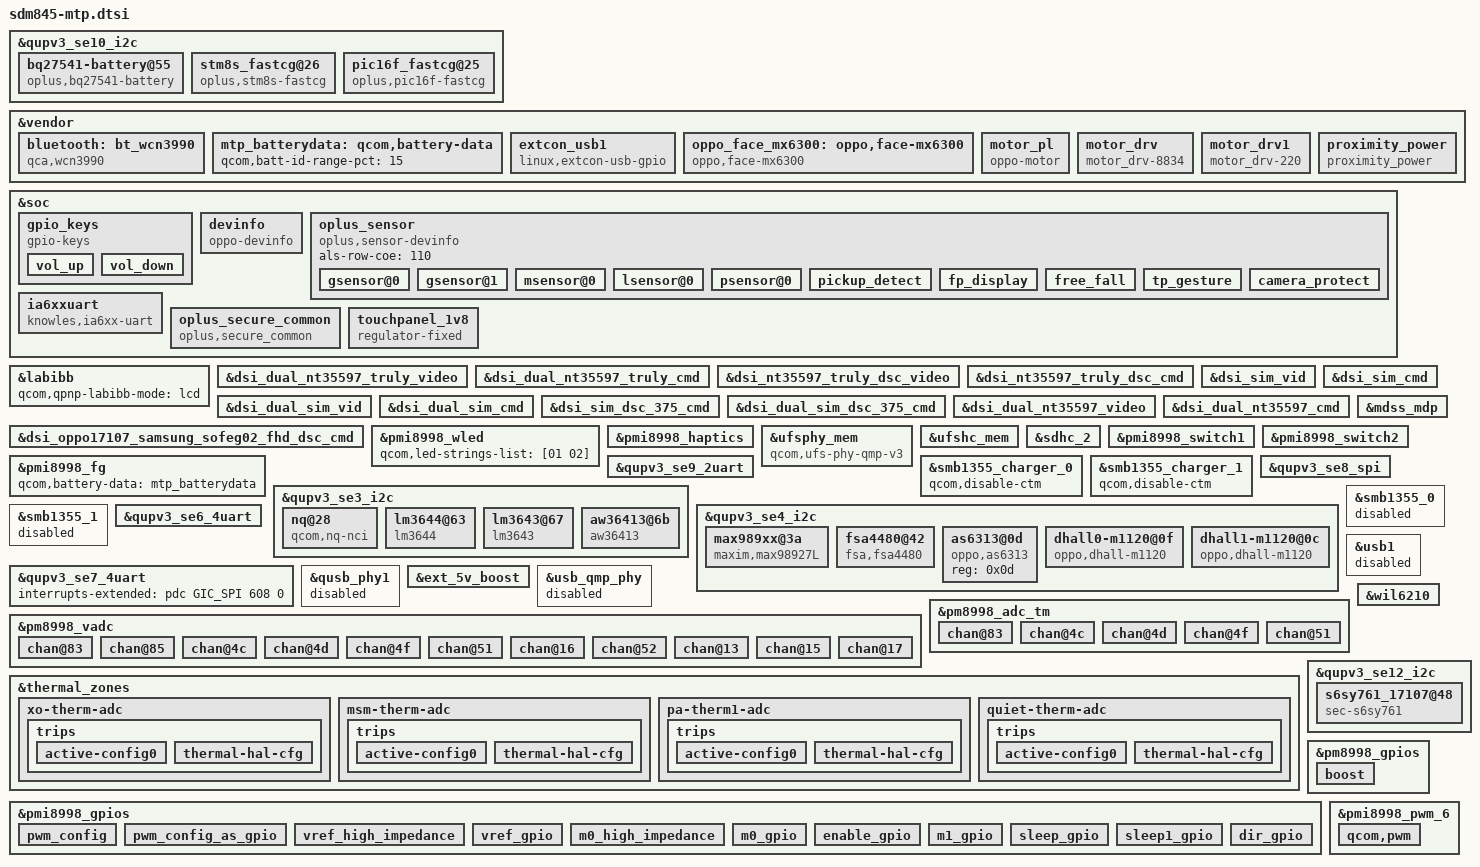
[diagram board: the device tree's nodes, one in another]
/* Copyright (c) 2016-2019, The Linux Foundation. All rights reserved.
 *
 * This program is free software; you can redistribute it and/or modify
 * it under the terms of the GNU General Public License version 2 and
 * only version 2 as published by the Free Software Foundation.
 *
 * This program is distributed in the hope that it will be useful,
 * but WITHOUT ANY WARRANTY; without even the implied warranty of
 * MERCHANTABILITY or FITNESS FOR A PARTICULAR PURPOSE.  See the
 * GNU General Public License for more details.
 */

#include <dt-bindings/gpio/gpio.h>
#include "sdm845-pmic-overlay.dtsi"
#include "sdm845-pinctrl-overlay.dtsi"
#include "sdm845-camera-sensor-mtp.dtsi"

&qupv3_se10_i2c {
#include "smb1355.dtsi"
};

&vendor {
	bluetooth: bt_wcn3990 {
		compatible = "qca,wcn3990";
		qca,bt-vdd-io-supply = <&pm8998_s3>;
		qca,bt-vdd-xtal-supply = <&pm8998_s5>;
		qca,bt-vdd-core-supply = <&pm8998_l7>;
		qca,bt-vdd-pa-supply = <&pm8998_l17>;
		qca,bt-vdd-ldo-supply = <&pm8998_l25>;

		qca,bt-vdd-io-voltage-level = <1352000 1352000>;
		qca,bt-vdd-xtal-voltage-level = <2040000 2040000>;
		qca,bt-vdd-core-voltage-level = <1800000 1800000>;
		qca,bt-vdd-pa-voltage-level = <1304000 1304000>;
		qca,bt-vdd-ldo-voltage-level = <3312000 3312000>;

		qca,bt-vdd-io-current-level = <1>; /* LPM/PFM */
		qca,bt-vdd-xtal-current-level = <1>; /* LPM/PFM */
		qca,bt-vdd-core-current-level = <1>; /* LPM/PFM */
		qca,bt-vdd-pa-current-level = <1>; /* LPM/PFM */
		qca,bt-vdd-ldo-current-level = <1>; /* LPM/PFM */
	};
};

&soc {
	gpio_keys {
		compatible = "gpio-keys";
		label = "gpio-keys";

		pinctrl-names = "default";
		pinctrl-0 = <&key_vol_up_default
			/*ifdef VENDOR_EDIT*/
			    &key_vol_down_default>;
			//#else
			//&key_cam_snapshot_default
			//&key_cam_focus_default>;
			/*endif*/

		vol_up {
			label = "volume_up";
			gpios = <&pm8998_gpios 6 GPIO_ACTIVE_LOW>;
			linux,input-type = <1>;
			linux,code = <115>;
			gpio-key,wakeup;
			debounce-interval = <15>;
			linux,can-disable;
		};
		/*ifdef VENDOR_EDIT*/
		vol_down {
			label = "volume_down";
			gpios = <&pm8998_gpios 5 GPIO_ACTIVE_LOW>;
			linux,input-type = <1>;
			linux,code = <114>;
			gpio-key,wakeup;
			debounce-interval = <15>;
			linux,can-disable;
		};
		/*endif*/

		/*
		cam_snapshot {
			label = "cam_snapshot";
			gpios = <&pm8998_gpios 7 GPIO_ACTIVE_LOW>;
			linux,input-type = <1>;
			linux,code = <766>;
			gpio-key,wakeup;
			debounce-interval = <15>;
			linux,can-disable;
		};

		cam_focus {
			label = "cam_focus";
			gpios = <&pm8998_gpios 8 GPIO_ACTIVE_LOW>;
			linux,input-type = <1>;
			linux,code = <528>;
			gpio-key,wakeup;
			debounce-interval = <15>;
			linux,can-disable;
		};
		*/
	};
	/*ifdef VENDOR_EDIT*/
	devinfo {
		compatible = "oppo-devinfo";
		Hw,sub_hwid_1 = <&tlmm 24 0x00>;
		Hw,high_version = <&tlmm 116 0x00>;
		pinctrl-names = "default","hw_sub_gpio_sleep", "high_version_active", "high_version_sleep";
		pinctrl-0 = <&hw_sub_gpio_active>;
		pinctrl-1 = <&hw_sub_gpio_sleep>;
		pinctrl-2 = <&hw_version_active>;
		pinctrl-3 = <&hw_version_sleep>;
	};
	/*endif*/


  //#ifdef VENDOR_EDIT
  /*yajie.chen @BSP.sensor, 2020/04/03, Add for sensor dts*/
  /*enum sensor_id { OPPO_ACCEL,OPPO_GYRO,OPPO_MAG,OPPO_LIGHT,OPPO_PROXIMITY,OPPO_SAR,OPPO_CT,OPPO_BAROMETER,SENSORS_NUM};*/
  oplus_sensor {
	compatible = "oplus,sensor-devinfo";
	als-row-coe = <110>;
	/*enum {LSM6DSM = 0x01, BMI160 = 0x02, LSM6DS3 = 0x04};*/
	gsensor@0 {
		sensor-name = <0x02>;//BMI160
		sensor-direction = <4>;
		sensor-index = <0>;//source num
		sensor-type = <0>;//OPPO_ACCEL
	};
	gsensor@1 {
		sensor-name = <0x01>;//LSM6DSM
		sensor-direction = <6>;
		sensor-index = <1>;//source num
		sensor-type = <0>;//OPPO_ACCEL
	};
	/* enum {AKM0991X = 0x01, MMC5603 = 0x02};*/
	msensor@0 {
		sensor-name = <0x01>;//AKM09918
		sensor-direction = <0>;
		sensor-index = <0>;
		sensor-type = <2>;//OPPO_MAG
		parameter-number= <18>;
		//soft-mag-parameter = <10489 0 194 0 95 1 194 0 9221 0 68 1 95 1 68 1 10344 0>;//e00 sign e01 sign...
	};
	/*enum {STK3A5X=0x01,TCS3701=0x02,TCS3408=0x04};*/
	lsensor@0 {
		sensor-name = <0x02>;//TCS3701
		sensor-index = <0>;
		sensor-type = <3>;//OPPO_MAG
		bus-number = <5>;
		irq-number = <89>;
		als-type = <2>;
		is-unit-device = <1>;
		is-als-dri = <1>;
		als-factor = <110>;
		is_als_initialed = <0>;
		als_buffer_length = <10>;
	};
	psensor@0 {
		sensor-name = <0x02>;//TCS3701
		sensor-index = <0>;
		sensor-type = <4>;//OPPO_PROXIMITY
		bus-number = <5>;
		irq-number = <89>;
		ps-cail-type = <2>;
		ps-type = <1>;
		is_ps_initialzed = <0>;
		low_step = <300>;
		high_step = <400>;
		low_limit = <400>;
		high_limit = <600>;
		dirty_low_step = <100>;
		dirty_high_step = <150>;
		ps_dirty_limit = <1020>;
		ps_ir_limit = <500>;
		ps_adjust_min = <0>;
		ps_adjust_max = <600>;
		sampling_count = <5>;
		step_max = <400>;
		step_min = <100>;
		step_div = <1500>;
		anti_shake_delta = <80>;
		dynamic_cali_max = <1024>;
		raw2offset_radio = <20800>;
		offset_max = <250>;
		offset_range_min = <0xFFFFFF01>;// -255
		offset_range_max = <255>;
		force_cali_limit = <2000>;
		cali_jitter_limit = <20>;
			cal_offset_margin = <80>;
		};
		/*virtual sensor
		enum sensor_algo_id {
			OPPO_PICKUP_DETECT,
			OPPO_LUX_AOD,
			OPPO_TP_GESTURE,
			OPPO_FP_DISPLAY,
			OPPO_FREE_FALL,
			OPPO_CAMERA_PROTECT,
			SENSOR_ALGO_NUM
		}*/
		pickup_detect {
			sensor-type = <0>; //OPPO_PICKUP_DETECT
			is-virtual-sensor;
			is-need-prox = <0>;
			prox-type = <0>; // 0 - proximity; 1 - proximity_fake
		};
		/*
		lux_aod {
			sensor-type = <1>; //OPPO_LUX_AOD
			is-virtual-sensor;
			thrd-low = <12>;
			thrd-high = <50>;
			als-type = <1>; // 0 - wise_light; 1 - ambient_light
		};
		*/
		fp_display {
			sensor-type = <3>; //OPPO_FP_DISPLAY
			is-virtual-sensor;
			prox-type = <0>; // 0 - proximity; 1 - proximity_fake
		};
		free_fall {
			sensor-type = <4>; //OPPO_FREE_FALL
			is-virtual-sensor;
		};
		tp_gesture {
			sensor-type = <2>; //OPPO_TP_GESTURE
			is-virtual-sensor;
		};
		camera_protect {
			sensor-type = <5>; //OPPO_CAMERA_PROTECT
			is-virtual-sensor;
			layout_offset_x = <65362>;
			layout_offset_y = <474>;
			init_pin = <17>;
			is_chip_pin = <0>;
		};
	};
	//#endif /*VENDOR_EDIT*/

/*#ifdef OPLUS_ARCH_EXTENDS */
	ia6xxuart {
		status = "ok";
		compatible = "knowles,ia6xx-uart";
		adnc,irq-pin = <&tlmm 80 0>;
		adnc,ldo-en-pin = <&tlmm 1 0>;
		adnc,reset = <&tlmm 25 0x00>;
		pinctrl-names = "default","adnc_reset_sleep";
		pinctrl-0 = <&adnc_reset_active>;
		pinctrl-1 = <&adnc_reset_sleep>;
	};
/*#endif OPLUS_ARCH_EXTENDS */

/* #ifdef OPLUS_FEATURE_SECURITY_COMMON */
	oplus_secure_common { //Slave driver and CS ID
                compatible = "oplus,secure_common"; //Manufacture, and Model
        };
/*#endif OPLUS_FEATURE_SECURITY_COMMON */
};


&labibb {
	status = "ok";
	qcom,qpnp-labibb-mode = "lcd";
};

&dsi_dual_nt35597_truly_video {
	qcom,panel-supply-entries = <&dsi_panel_pwr_supply>;
	qcom,mdss-dsi-bl-pmic-control-type = "bl_ctrl_wled";
	qcom,mdss-dsi-bl-min-level = <1>;
	qcom,mdss-dsi-bl-max-level = <4095>;
	qcom,mdss-dsi-mode-sel-gpio-state = "dual_port";
	qcom,panel-mode-gpio = <&tlmm 52 0>;
	qcom,platform-reset-gpio = <&tlmm 6 0>;
};

&dsi_dual_nt35597_truly_cmd {
	qcom,panel-supply-entries = <&dsi_panel_pwr_supply>;
	qcom,mdss-dsi-bl-pmic-control-type = "bl_ctrl_wled";
	qcom,mdss-dsi-bl-min-level = <1>;
	qcom,mdss-dsi-bl-max-level = <4095>;
	qcom,mdss-dsi-mode-sel-gpio-state = "dual_port";
	qcom,panel-mode-gpio = <&tlmm 52 0>;
	qcom,platform-reset-gpio = <&tlmm 6 0>;
	qcom,platform-te-gpio = <&tlmm 10 0>;
};

&dsi_nt35597_truly_dsc_video {
	qcom,panel-supply-entries = <&dsi_panel_pwr_supply>;
	qcom,mdss-dsi-bl-pmic-control-type = "bl_ctrl_wled";
	qcom,mdss-dsi-bl-min-level = <1>;
	qcom,mdss-dsi-bl-max-level = <4095>;
	qcom,mdss-dsi-mode-sel-gpio-state = "single_port";
	qcom,panel-mode-gpio = <&tlmm 52 0>;
	qcom,platform-reset-gpio = <&tlmm 6 0>;
};

&dsi_nt35597_truly_dsc_cmd {
	qcom,panel-supply-entries = <&dsi_panel_pwr_supply>;
	qcom,mdss-dsi-bl-pmic-control-type = "bl_ctrl_wled";
	qcom,mdss-dsi-bl-min-level = <1>;
	qcom,mdss-dsi-bl-max-level = <4095>;
	qcom,mdss-dsi-mode-sel-gpio-state = "single_port";
	qcom,panel-mode-gpio = <&tlmm 52 0>;
	qcom,platform-reset-gpio = <&tlmm 6 0>;
	qcom,platform-te-gpio = <&tlmm 10 0>;
};

&dsi_sim_vid {
	qcom,panel-supply-entries = <&dsi_panel_pwr_supply>;
	qcom,mdss-dsi-bl-pmic-control-type = "bl_ctrl_wled";
	qcom,platform-reset-gpio = <&tlmm 6 0>;
};

&dsi_dual_sim_vid {
	qcom,panel-supply-entries = <&dsi_panel_pwr_supply>;
	qcom,mdss-dsi-bl-pmic-control-type = "bl_ctrl_wled";
	qcom,platform-reset-gpio = <&tlmm 6 0>;
};

&dsi_sim_cmd {
	qcom,panel-supply-entries = <&dsi_panel_pwr_supply>;
	qcom,mdss-dsi-bl-pmic-control-type = "bl_ctrl_wled";
	qcom,platform-reset-gpio = <&tlmm 6 0>;
};

&dsi_dual_sim_cmd {
	qcom,panel-supply-entries = <&dsi_panel_pwr_supply>;
	qcom,mdss-dsi-bl-pmic-control-type = "bl_ctrl_wled";
	qcom,platform-reset-gpio = <&tlmm 6 0>;
};

&dsi_sim_dsc_375_cmd {
	qcom,panel-supply-entries = <&dsi_panel_pwr_supply>;
	qcom,mdss-dsi-bl-pmic-control-type = "bl_ctrl_wled";
	qcom,platform-reset-gpio = <&tlmm 6 0>;
};

&dsi_dual_sim_dsc_375_cmd {
	qcom,panel-supply-entries = <&dsi_panel_pwr_supply>;
	qcom,mdss-dsi-bl-pmic-control-type = "bl_ctrl_wled";
	qcom,platform-reset-gpio = <&tlmm 6 0>;
};

&dsi_dual_nt35597_video {
	qcom,panel-supply-entries = <&dsi_panel_pwr_supply>;
	qcom,mdss-dsi-bl-pmic-control-type = "bl_ctrl_wled";
	qcom,mdss-dsi-bl-min-level = <1>;
	qcom,mdss-dsi-bl-max-level = <4095>;
	qcom,mdss-dsi-mode-sel-gpio-state = "dual_port";
	qcom,panel-mode-gpio = <&tlmm 52 0>;
	qcom,platform-reset-gpio = <&tlmm 6 0>;
};

&dsi_dual_nt35597_cmd {
	qcom,panel-supply-entries = <&dsi_panel_pwr_supply>;
	qcom,mdss-dsi-bl-pmic-control-type = "bl_ctrl_wled";
	qcom,mdss-dsi-bl-min-level = <1>;
	qcom,mdss-dsi-bl-max-level = <4095>;
	qcom,mdss-dsi-mode-sel-gpio-state = "dual_port";
	qcom,panel-mode-gpio = <&tlmm 52 0>;
	qcom,platform-reset-gpio = <&tlmm 6 0>;
	qcom,platform-te-gpio = <&tlmm 10 0>;
};

//&dsi_nt35597_truly_dsc_cmd_display {
//	qcom,dsi-display-active;
//};

&dsi_oppo17107_samsung_sofeg02_fhd_dsc_cmd{
	qcom,dsi-display-active;
};

//#ifdef VENDOR_EDIT
&dsi_oppo17107_samsung_sofeg02_fhd_dsc_cmd{
	qcom,panel-supply-entries = <&dsi_panel_pwr_supply_no_labibb>;
        qcom,panel-supply-oppo-hardware-march = <&dsi_panel_pwr_supply_vdd_no_labibb>;

	qcom,mdss-dsi-bl-min-level = <1>;
	qcom,mdss-dsi-mode-sel-gpio-state = "single_port";
	qcom,panel-mode-gpio = <&tlmm 52 0>;
	qcom,platform-te-gpio = <&tlmm 10 0>;
	qcom,platform-reset-gpio = <&tlmm 6 0>;
	qcom,platform-vci-control-gpio = <&tlmm 26 0>;
	//qcom,platform-poc-control-gpio = <&tlmm 25 0>;
};

&pmi8998_wled {
	status = "okay";
	qcom,led-strings-list = [01 02];
};

&pmi8998_haptics {
	status = "okay";
};

&mdss_mdp {
	#cooling-cells = <2>;
};

&ufsphy_mem {
	compatible = "qcom,ufs-phy-qmp-v3";

	vdda-phy-supply = <&pm8998_l1>; /* 0.88v */
	vdda-pll-supply = <&pm8998_l26>; /* 1.2v */
	vdda-phy-max-microamp = <62900>;
	vdda-pll-max-microamp = <18300>;

	status = "ok";
};

&ufshc_mem {
	vdd-hba-supply = <&ufs_phy_gdsc>;
	vdd-hba-fixed-regulator;
	vcc-supply = <&pm8998_l20>;
	vcc-voltage-level = <2950000 2960000>;
	vccq2-supply = <&pm8998_s4>;
	vcc-max-microamp = <600000>;
	vccq2-max-microamp = <600000>;

	qcom,vddp-ref-clk-supply = <&pm8998_l2>;
	qcom,vddp-ref-clk-max-microamp = <100>;

	status = "ok";
};

&sdhc_2 {
	vdd-supply = <&pm8998_l21>;
	qcom,vdd-voltage-level = <2950000 2960000>;
	qcom,vdd-current-level = <200 800000>;

	vdd-io-supply = <&pm8998_l13>;
	qcom,vdd-io-voltage-level = <1808000 2960000>;
	qcom,vdd-io-current-level = <200 22000>;

	pinctrl-names = "active", "sleep", "ds_400KHz",
			"ds_50MHz", "ds_100MHz", "ds_200MHz";
	pinctrl-0 = <&sdc2_clk_on  &sdc2_cmd_on &sdc2_data_on &storage_cd>;
	pinctrl-1 = <&sdc2_clk_off &sdc2_cmd_off &sdc2_data_off &storage_cd>;
	pinctrl-2 = <&sdc2_clk_ds_400KHz
			&sdc2_cmd_ds_400KHz &sdc2_data_ds_400KHz>;
	pinctrl-3 = <&sdc2_clk_ds_50MHz
			&sdc2_cmd_ds_50MHz &sdc2_data_ds_50MHz>;
	pinctrl-4 = <&sdc2_clk_ds_100MHz
			&sdc2_cmd_ds_100MHz &sdc2_data_ds_100MHz>;
	pinctrl-5 = <&sdc2_clk_ds_200MHz
			&sdc2_cmd_ds_200MHz &sdc2_data_ds_200MHz>;

	cd-gpios = <&tlmm 126 GPIO_ACTIVE_LOW>;

	status = "ok";
};

&pmi8998_switch1 {
	pinctrl-names = "led_enable", "led_disable";
	pinctrl-0 = <&flash_led3_front_en>;
	pinctrl-1 = <&flash_led3_front_dis>;
};

&pmi8998_switch2 {
	pinctrl-names = "led_enable", "led_disable";
	pinctrl-0 = <&flash_led3_iris_en>;
	pinctrl-1 = <&flash_led3_iris_dis>;
};

&vendor {
	mtp_batterydata: qcom,battery-data {
		qcom,batt-id-range-pct = <15>;
		#include "fg-gen3-batterydata-itech-3000mah.dtsi"
		#include "fg-gen3-batterydata-ascent-3450mah.dtsi"
		#include "fg-gen3-batterydata-demo-6000mah.dtsi"
	};

	extcon_usb1: extcon_usb1 {
		compatible = "linux,extcon-usb-gpio";
		vbus-gpio = <&pmi8998_gpios 8 GPIO_ACTIVE_HIGH>;

		pinctrl-names = "default";
		pinctrl-0 = <&usb2_vbus_det_default>;
	};
};

&pmi8998_fg {
	qcom,battery-data = <&mtp_batterydata>;
};

&smb1355_charger_0 {
	status = "ok";
	qcom,disable-ctm;
};

&smb1355_charger_1 {
	status = "ok";
	qcom,disable-ctm;
};

&qupv3_se9_2uart {
	status = "ok";
};

&qupv3_se8_spi {
	status = "ok";
};

&qupv3_se3_i2c {
	status = "ok";
	nq@28 {
		compatible = "qcom,nq-nci";
		reg = <0x28>;
		qcom,nq-irq = <&tlmm 63 0x00>;
		qcom,nq-ven = <&tlmm 12 0x00>;
		qcom,nq-firm = <&tlmm 62 0x00>;
		qcom,nq-clkreq = <&pm8998_gpios 21 0x00>;
		qcom,nq-esepwr = <&tlmm 116 0x00>;
		interrupt-parent = <&tlmm>;
		interrupts = <63 0>;
		interrupt-names = "nfc_irq";
		pinctrl-names = "nfc_active", "nfc_suspend";
		pinctrl-0 = <&nfc_int_active
			     &nfc_enable_active
			     &nfc_clk_default>;
		pinctrl-1 = <&nfc_int_suspend &nfc_enable_suspend>;
	};
};

/* #ifdef OPLUS_ARCH_EXTENDS */
&qupv3_se4_i2c {
	status = "ok";
	max989xx@3a {
		compatible = "maxim,max98927L";
		reg = <0x3a>;
		mono_stereo_mode = <0>;
		interleave_mode = <0>;
		maxim,98927-reset-gpio = <&tlmm 69 0x00>;
		max989xx_vdd-supply = <&pm8998_s4>;
		status = "okay";
	};
};
/* #endif OPLUS_ARCH_EXTENDS */




//#ifdef VENDOR_EDIT
&smb1355_0 {
	status = "disabled";
};
&smb1355_1 {
	status = "disabled";
};
//#endif //VENDOR_EDIT

/* #ifdef OPLUS_FEATURE_FACERECOGNITION  */
&qupv3_se3_i2c {
        status = "ok";
        lm3644@63 {
                compatible = "lm3644";
                reg = <0x63>;
                lm3644,hwen-gpio = <&tlmm 39 0x00>;
                lm3644,ldo-en-gpio = <&tlmm 40 0x00>;
                lm3644,watchdog-gpio = <&tlmm 81 0x00>;
                lm3644,watchdog-en-gpio = <&tlmm 33 0x00>;
                status = "okay";
        };
        lm3643@67 {
                compatible = "lm3643";
                reg = <0x67>;
                lm3643,hwen-gpio = <&tlmm 113 0x00>;
                status = "okay";
        };
        aw36413@6b {
                compatible = "aw36413";
                reg = <0x6b>;
                aw36413,hwen-gpio = <&tlmm 113 0x00>;
                status = "okay";
        };
};
/* #endif OPLUS_FEATURE_FACERECOGNITION  */

/* #ifdef OPLUS_ARCH_EXTENDS */
&qupv3_se4_i2c {
	status = "ok";
	fsa4480@42 {
		compatible = "fsa,fsa4480";
		reg = <0x42>;
		interrupts = <52 0>;
		oppo,fsa4480-irq = <&tlmm 52 0x00>;
		interrupt-names = "fsa4480_irq";
		status = "okay";
	};
};

&qupv3_se4_i2c {
	status = "ok";
	as6313@0d {
		compatible = "oppo,as6313";
		reg = <0x0d>;
		status = "okay";
	};
};

/* #endif OPLUS_ARCH_EXTENDS */

&qupv3_se10_i2c {
	status = "ok";
//#ifdef VENDOR_EDIT
	pinctrl-names = "default", "sleep", "pulldown", "pullup";
	pinctrl-2 = <&qupv3_se10_i2c_pulldown>;
	pinctrl-3 = <&qupv3_se10_i2c_pullup>;
//#endif //VENDOR_EDIT

//#ifdef VENDOR_EDIT
	bq27541-battery@55 {
		status = "okay";
		compatible = "oplus,bq27541-battery";
		reg = <0x55>;
		qcom,modify-soc-smooth;
//		qcom,batt_bq28z610;
	};

	stm8s_fastcg@26{
		status = "okay";
		compatible = "oplus,stm8s-fastcg";
		reg = <0x26>;
		qcom,oplus_batt_4400mv;
		qcom,vooc_fw_update_newmethod;
		qcom,vooc-fw-type = <5>;
		qcom,vooc-low-temp = <120>;
		qcom,vooc-high-temp = <430>;
		qcom,vooc-low-soc = <1>;
		qcom,vooc-high-soc = <85>;

		pinctrl-names = "switch1_act_switch2_act", "switch1_sleep_switch2_sleep",
						"switch1_act_switch3_act", "switch1_sleep_switch3_sleep",
						"switch1_act_switch2_sleep", "switch1_sleep_switch2_act",
						"clock_active","clock_sleep",
						"data_active","data_sleep",
						"reset_active","reset_sleep";
		pinctrl-0 = <&charging_switch1_active>;
		pinctrl-1 = <&charging_switch1_sleep >;
		pinctrl-2 = <&charging_switch1_active>;
		pinctrl-3 = <&charging_switch1_sleep >;
		pinctrl-4 = <&charging_switch1_active>;
		pinctrl-5 = <&charging_switch1_sleep>;
		pinctrl-6 = <&charging_clock_active >;
		pinctrl-7 = <&charging_clock_sleep >;
		pinctrl-8 = <&charging_data_active >;
		pinctrl-9 = <&charging_data_sleep >;
		pinctrl-10 = <&charging_reset_active >;
		pinctrl-11 = <&charging_reset_sleep >;

		qcom,charging_switch1-gpio = <&tlmm 51 0x00>;
		//qcom,charging_switch2-gpio = <&tlmm 113 0x00>;
		//qcom,charging_switch3-gpio = <&tlmm 38 0x00>;

		qcom,charging_reset-gpio = <&tlmm 102 0x00>;
		qcom,charging_clock-gpio = <&tlmm 43 0x00>;
		qcom,charging_data-gpio = <&tlmm 44 0x00>;
	};

	pic16f_fastcg@25{
		status = "okay";
		compatible = "oplus,pic16f-fastcg";
		reg = <0x25>;

		pinctrl-names = "switch1_act_switch2_act", "switch1_sleep_switch2_sleep",
						"switch1_act_switch3_act", "switch1_sleep_switch3_sleep",
						"switch1_act_switch2_sleep", "switch1_sleep_switch2_act",
						"clock_active","clock_sleep",
						"data_active","data_sleep",
						"reset_active","reset_sleep";
		pinctrl-0 = <&charging_switch1_active>;
		pinctrl-1 = <&charging_switch1_sleep >;
		pinctrl-2 = <&charging_switch1_active>;
		pinctrl-3 = <&charging_switch1_sleep >;
		pinctrl-4 = <&charging_switch1_active>;
		pinctrl-5 = <&charging_switch1_sleep>;
		pinctrl-6 = <&charging_clock_active >;
		pinctrl-7 = <&charging_clock_sleep >;
		pinctrl-8 = <&charging_data_active >;
		pinctrl-9 = <&charging_data_sleep >;
		pinctrl-10 = <&charging_reset_active >;
		pinctrl-11 = <&charging_reset_sleep >;

		qcom,charging_switch1-gpio = <&tlmm 51 0x00>;
		//qcom,charging_switch2-gpio = <&tlmm 113 0x00>;
		//qcom,charging_switch3-gpio = <&tlmm 38 0x00>;

		qcom,charging_reset-gpio = <&tlmm 102 0x00>;
		qcom,charging_clock-gpio = <&tlmm 43 0x00>;
		qcom,charging_data-gpio = <&tlmm 44 0x00>;
	};
//#endif //VENDOR_EDIT
};

&qupv3_se6_4uart {
	status = "ok";
};
/* #ifdef OPLUS_ARCH_EXTENDS */
&qupv3_se7_4uart{
	status = "ok";
	interrupts-extended = <&pdc GIC_SPI 608 0>;
};
/*#endif OPLUS_ARCH_EXTENDS */
&usb1 {
//#ifdef VENDOR_EDIT
	//status = "okay";
	status = "disabled";
//#endif
	//#ifdef VENDOR_EDIT
	//extcon = <&extcon_usb1>;
};
&qusb_phy1 {
//#ifdef VENDOR_EDIT
	//status = "okay";
	status = "disabled";
	//#endif
};

&ext_5v_boost {
	status = "ok";
};
&usb_qmp_phy {
//#ifdef VENDOR_EDIT
	//status = "okay";
	status = "disabled";
//#endif
};

&pm8998_vadc {
	chan@83 {
		label = "vph_pwr";
		reg = <0x83>;
		qcom,decimation = <2>;
		qcom,pre-div-channel-scaling = <1>;
		qcom,calibration-type = "absolute";
		qcom,scale-function = <0>;
		qcom,hw-settle-time = <0>;
		qcom,fast-avg-setup = <0>;
	};

	chan@85 {
		label = "vcoin";
		reg = <0x85>;
		qcom,decimation = <2>;
		qcom,pre-div-channel-scaling = <1>;
		qcom,calibration-type = "absolute";
		qcom,scale-function = <0>;
		qcom,hw-settle-time = <0>;
		qcom,fast-avg-setup = <0>;
	};

	chan@4c {
		label = "xo_therm";
		reg = <0x4c>;
		qcom,decimation = <2>;
		qcom,pre-div-channel-scaling = <0>;
		qcom,calibration-type = "ratiometric";
		qcom,scale-function = <4>;
		qcom,hw-settle-time = <2>;
		qcom,fast-avg-setup = <0>;
	};

	chan@4d {
		label = "msm_therm";
		reg = <0x4d>;
		qcom,decimation = <2>;
		qcom,pre-div-channel-scaling = <0>;
		qcom,calibration-type = "ratiometric";
		qcom,scale-function = <2>;
		qcom,hw-settle-time = <2>;
		qcom,fast-avg-setup = <0>;
	};

	chan@4f {
		label = "pa_therm1";
		reg = <0x4f>;
		qcom,decimation = <2>;
		qcom,pre-div-channel-scaling = <0>;
		qcom,calibration-type = "ratiometric";
		qcom,scale-function = <2>;
		qcom,hw-settle-time = <2>;
		qcom,fast-avg-setup = <0>;
	};


	chan@51 {
		label = "quiet_therm";
		reg = <0x51>;
		qcom,decimation = <2>;
		qcom,pre-div-channel-scaling = <0>;
		qcom,calibration-type = "ratiometric";
		qcom,scale-function = <2>;
		qcom,hw-settle-time = <2>;
		qcom,fast-avg-setup = <0>;
	};

//#ifdef VENDOR_EDIT
	chan@16 {
		label = "gpio12_adc";
		reg = <0x16>;
		qcom,decimation = <2>;
		qcom,pre-div-channel-scaling = <0>;//1:1 scaling
		qcom,calibration-type = "absolute";
		qcom,scale-function = <0>;
		qcom,hw-settle-time = <2>;
		qcom,fast-avg-setup = <0>;
	};
//#endif /* VENDOR_EDIT */
//#ifdef VENDOR_EDIT
	chan@52 {
		label = "gpio8_adc";
		reg = <0x52>;
		qcom,decimation = <2>;
		qcom,pre-div-channel-scaling = <0>;//1:1 scaling
		qcom,calibration-type = "absolute";
		qcom,scale-function = <0>;
		qcom,hw-settle-time = <2>;
		qcom,fast-avg-setup = <0>;
	};
//#endif /* VENDOR_EDIT */
//#ifdef OPLUS_FEATURE_FACERECOGNITION
	chan@13 {
		label = "gpio9_adc";
		reg = <0x13>;
		qcom,decimation = <2>;
		qcom,pre-div-channel-scaling = <0>;//1:1 scaling
		qcom,calibration-type = "absolute";
		qcom,scale-function = <0>;
		qcom,hw-settle-time = <2>;
		qcom,fast-avg-setup = <0>;
	};
//#endif /* OPLUS_FEATURE_FACERECOGNITION  */
//#ifdef OPLUS_FEATURE_FACERECOGNITION
	chan@15 {
		label = "gpio11_adc";
		reg = <0x15>;
		qcom,decimation = <2>;
		qcom,pre-div-channel-scaling = <0>;//1:1 scaling
		qcom,calibration-type = "absolute";
		qcom,scale-function = <0>;
		qcom,hw-settle-time = <2>;
		qcom,fast-avg-setup = <0>;
	};
	chan@17 {
		label = "gpio21_adc";
		reg = <0x17>;
		qcom,decimation = <2>;
		qcom,pre-div-channel-scaling = <0>;//1:1 scaling
		qcom,calibration-type = "absolute";
		qcom,scale-function = <0>;
		qcom,hw-settle-time = <2>;
		qcom,fast-avg-setup = <0>;
	};
//#endif /* OPLUS_FEATURE_FACERECOGNITION  */
};

&pm8998_adc_tm {
	chan@83 {
		label = "vph_pwr";
		reg = <0x83>;
		qcom,pre-div-channel-scaling = <1>;
		qcom,calibration-type = "absolute";
		qcom,scale-function = <0>;
		qcom,hw-settle-time = <0>;
		qcom,btm-channel-number = <0x60>;
	};

	chan@4c {
		label = "xo_therm";
		reg = <0x4c>;
		qcom,pre-div-channel-scaling = <0>;
		qcom,calibration-type = "ratiometric";
		qcom,scale-function = <4>;
		qcom,hw-settle-time = <2>;
		qcom,btm-channel-number = <0x68>;
		qcom,thermal-node;
	};

	chan@4d {
		label = "msm_therm";
		reg = <0x4d>;
		qcom,pre-div-channel-scaling = <0>;
		qcom,calibration-type = "ratiometric";
		qcom,scale-function = <2>;
		qcom,hw-settle-time = <2>;
		qcom,btm-channel-number = <0x70>;
		qcom,thermal-node;
	};

	chan@4f {
		label = "pa_therm1";
		reg = <0x4f>;
		qcom,pre-div-channel-scaling = <0>;
		qcom,calibration-type = "ratiometric";
		qcom,scale-function = <2>;
		qcom,hw-settle-time = <2>;
		qcom,btm-channel-number = <0x78>;
		qcom,thermal-node;
	};

	chan@51 {
		label = "quiet_therm";
		reg = <0x51>;
		qcom,pre-div-channel-scaling = <0>;
		qcom,calibration-type = "ratiometric";
		qcom,scale-function = <2>;
		qcom,hw-settle-time = <2>;
		qcom,btm-channel-number = <0x80>;
		qcom,thermal-node;
	};
};

&thermal_zones {
	xo-therm-adc {
		polling-delay-passive = <0>;
		polling-delay = <0>;
		thermal-sensors = <&pm8998_adc_tm 0x4c>;
		wake-capable-sensor;
		thermal-governor = "user_space";

		trips {
			active-config0 {
				temperature = <125000>;
				hysteresis = <10000>;
				type = "passive";
			};
					thermal-hal-cfg {
				temperature = <115000>;
				hysteresis = <5000>;
				type = "passive";
			};
		};
	};

	msm-therm-adc {
		polling-delay-passive = <0>;
		polling-delay = <0>;
		thermal-sensors = <&pm8998_adc_tm 0x4d>;
		wake-capable-sensor;
		thermal-governor = "user_space";

		trips {
			active-config0 {
				temperature = <125000>;
				hysteresis = <10000>;
				type = "passive";
			};
					thermal-hal-cfg {
				temperature = <115000>;
				hysteresis = <5000>;
				type = "passive";
			};
		};
	};

	pa-therm1-adc {
		polling-delay-passive = <0>;
		polling-delay = <0>;
		thermal-sensors = <&pm8998_adc_tm 0x4f>;
		wake-capable-sensor;
		thermal-governor = "user_space";

		trips {
			active-config0 {
				temperature = <125000>;
				hysteresis = <10000>;
				type = "passive";
			};
					thermal-hal-cfg {
				temperature = <115000>;
				hysteresis = <5000>;
				type = "passive";
			};
		};
	};

	quiet-therm-adc {
		polling-delay-passive = <0>;
		polling-delay = <0>;
		thermal-sensors = <&pm8998_adc_tm 0x51>;
		wake-capable-sensor;
		thermal-governor = "user_space";

		trips {
			active-config0 {
				temperature = <125000>;
				hysteresis = <10000>;
				type = "passive";
			};
					thermal-hal-cfg {
				temperature = <115000>;
				hysteresis = <5000>;
				type = "passive";
			};
		};
	};
};

&wil6210 {
	status = "ok";
};

//#ifdef VENDOR_EDIT
&qupv3_se12_i2c {
	status = "okay";
	s6sy761_17107@48 {
		compatible = "sec-s6sy761";
		reg = <0x48>;
		chip-name = "S6SY761";

		/* Interrupt && Irq-gpio */
		interrupt-parent = <&tlmm>;
		interrupts = <125 0x2008>;

		/* Power Config */
		enable2v8_gpio = <&tlmm 26 0x1>;
		//enable1v8_gpio = <&tlmm 32 0x1>;
		vdd_2v8-supply = <&pm8998_l28>;
		vcc_1v8-supply = <&touchpanel_1v8>;
		vdd_2v8_volt = <3300000>;

		/* Other HW Resource */
		irq-gpio = <&tlmm 125 0x2008>;
		reset-gpio = <&tlmm 99 0x1>;
		pinctrl-names = "default";
		pinctrl-0 = <&ts_int_active &ts_reset_active &ts_1v8_active>;

		touchpanel,max-num-support = <10>;
		touchpanel,tx-rx-num = <17 37>;
		earsense,tx-rx-num = <17 18>;
		touchpanel,panel-coords = <1080 2340>;
		touchpanel,display-coords = <1080 2340>;
		touchpanel,touchmajor-limit = <32 54>;

		/* SW Support Feature Control */
		ear_sense_support;
		black_gesture_support;
		fw_edge_limit_support;
		charger_pump_support;
		//spurious_fingerprint_support;
		fw_update_app_support;
		smart_gesture_support;
		game_switch_support;
		kernel_grip_support_special;
		auto_test_need_cal_support;

		/*
		 *Virtual Key Config:
		 *1:touchpanel,button-type: <virtualkey_type  supportted_button-map>
		 *virtualkey_type:
		 *Type 1: using board_properties
		 *Type 2: using same IC (button zone&& touch zone are seprate)
		 *Type 3: using diffrent IC (button zone&& touch zone are seprate)
		 *Type 4: No need of virtual key process
		 *supportted_button-map:select|menu|home|back
		 *
		 *2:touchpanel,button-map
		 *type (X1,Y1)(X2,Y2)(X3,Y3)(Width_X,Hight_Y)--Only when button-type is 0
		 */
		touchpanel,button-type = <4>;
		touchpanel.button-TRx = <0 0>;
	};
};

&soc {
	touchpanel_1v8: touchpanel_1v8 {
		compatible = "regulator-fixed";
		regulator-name = "touchpanel_1v8";
		startup-delay-us = <0>;
		enable-active-high;
		gpio = <&tlmm 32 0>;
	};
};
//#endif

/* #ifdef OPLUS_FEATURE_FACERECOGNITION  */
&vendor  {
    oppo_face_mx6300: oppo,face-mx6300 {
        compatible = "oppo,face-mx6300";

        /* mx6300 */
        mx6300_IR_CAMIO-supply = <&pm8998_lvs1>;
        mx6300,IR_ACAMD_2V8-gpio = <&tlmm 133 0>;
        mx6300,IR_VCAMD_1V2-gpio = <&tlmm 100 0>;
        mx6300,IR_PWDN-gpio = <&tlmm 35 0>;
        mx6300,MX_VISP_VDD_0V9-gpio = <&tlmm 123 0>;
        mx6300,MX_VISP_VDD1_0V9-gpio = <&tlmm 83 0>;
        mx6300,MX_VISP_VDDIO_1V8-gpio = <&tlmm 128 0>;
        mx6300,MX_reset-gpio = <&tlmm 62 0>;
        mx6300,MX_VDDIO_1V8-gpio = <&tlmm 2 0>;
        mx6300,MX_tstmode-gpio = <&tlmm 77 0>;
    };
};
/* #endif OPLUS_FEATURE_FACERECOGNITION  */

//#ifdef VENDOR_EDIT
&qupv3_se4_i2c {
	status = "okay";
	dhall0-m1120@0f {
		compatible = "oppo,dhall-m1120";
		reg = <0x0c>;
		pinctrl-names = "hall_power_down","hall_power_up","hall0_interrupt_input";
		pinctrl-0 = <&hall_power_down>;
		pinctrl-1 = <&hall_power_up>;
		pinctrl-2 = <&hall0_interrupt_input>;
		interrupt-parent = <&tlmm>;
		interrupts = <124 0x2>;
		dhall,irq-gpio = <&tlmm 124 0x2008>;
		dhall,id = <0>;
		vdd_2v8-supply = <&pm8998_l19>;//VREG_L19A_3P0
		vcc_1v8-supply = <&pm8998_s4>;//VREG_S4A_1P8
		qcom,hall-power-gpio = <&tlmm 21 0>;
	};
	dhall1-m1120@0c {
		compatible = "oppo,dhall-m1120";
		reg = <0x0f>;
		pinctrl-names = "hall_power_down","hall_power_up","hall1_interrupt_input";
		pinctrl-0 = <&hall_power_down>;
		pinctrl-1 = <&hall_power_up>;
		pinctrl-2 = <&hall1_interrupt_input>;
		interrupt-parent = <&tlmm>;
		interrupts = <92 0x2>;
		dhall,irq-gpio = <&tlmm 92 0x2008>;
		dhall,id = <1>;
		vdd_2v8-supply = <&pm8998_l19>;//VREG_L19A_3P0
		vcc_1v8-supply = <&pm8998_s4>;//VREG_S4A_1P8
		qcom,hall-power-gpio = <&tlmm 21 0>;
	};
};

&pm8998_gpios {
	boost: boost {
		pins = "gpio7";
		function = "normal";
		bias-pull-down; //pull down
		power-source = <0>; // VIN0,1.8V
		output-low; //digital output, no invert
		qcom,drive-strength = <3>;//0.15
	};
};

&pmi8998_gpios {
	//pwm mode
	pwm_config: pwm_config {
		pins = "gpio8";//GPIO 8
		function = "func1";//Special Function 1,pwm
		bias-disable; //No Pull
		power-source = <0>;//VIN0
		output-low; //digital output, no invert
		qcom,drive-strength = <3>; //LOW strength
		drive-push-pull;//CMOS
	};
	//gpio mode for stspin220
	pwm_config_as_gpio: pwm_config_as_gpio {
		pins = "gpio8";//GPIO 8
		function = "normal";//
		bias-disable; //No Pull
		power-source = <0>;//VIN0
		output-low; //digital output, no invert
		qcom,drive-strength = <3>; //LOW strength
		drive-push-pull;//CMOS
	};
	//vref_gpio
	vref_high_impedance: vref_high_impedance {
		pins = "gpio10";
		function = "normal";
		bias-disable; /* No Pull */
		power-source = <0>; /* VIN0 1.8V*/
		output-low; /* digital output, no invert */
		qcom,drive-strength = <1>; /* high strength */
		drive-push-pull; /* CMOS */
		bias-high-impedance;//high_impedance mode
	};
	vref_gpio: vref_gpio {
		pins = "gpio10";
		function = "normal";
		bias-disable; /* No Pull */
		power-source = <0>; /* VIN0 1.8V*/
		output-low; /* digital output, no invert */
		qcom,drive-strength = <1>; /* high strength */
		drive-push-pull; /* CMOS */
	};
	//m0-gpio
	m0_high_impedance: m0_high_impedance {
		pins = "gpio3";
		function = "normal";
		bias-disable; /* No Pull */
		power-source = <0>; /* VIN0 3.6V*/
		output-low; /* digital output, no invert */
		qcom,drive-strength = <3>; /* LOW strength */
		drive-push-pull; /* CMOS */
		bias-high-impedance;//high_impedance mode
	};
	m0_gpio: m0_gpio {
		pins = "gpio3";
		function = "normal";
		bias-disable; /* No Pull */
		power-source = <0>; /* VIN0 3.6V*/
		output-low; /* digital output, no invert */
		qcom,drive-strength = <3>; /* LOW strength */
		drive-push-pull; /* CMOS */
	};
	//for stspin220
	enable_gpio: enable_gpio {
		pins = "gpio3";
		function = "normal";
		bias-disable; /* No Pull */
		power-source = <0>; /* VIN0 3.6V*/
		output-low; /* digital output, no invert */
		qcom,drive-strength = <3>; /* LOW strength */
		drive-push-pull; /* CMOS */
	};
	//m1-gpio
	m1_gpio: m1_gpio {
		pins = "gpio11";
		function = "normal";
		bias-disable; /* No Pull */
		power-source = <0>; /* VIN0 3.6V*/
		output-low; /* digital output, no invert */
		qcom,drive-strength = <3>; /* LOW strength */
		drive-push-pull; /* CMOS */
	};
	//sleep-gpio
	sleep_gpio: sleep_gpio {
		pins = "gpio1";
		function = "normal";
		bias-disable; /* No Pull */
		power-source = <0>; /* VIN0 3.6V*/
		output-low; /* digital output, no invert */
		qcom,drive-strength = <3>; /* LOW strength */
		drive-push-pull; /* CMOS */
	};
	//sleep1-gpio
	sleep1_gpio: sleep1_gpio {
		pins = "gpio7";
		function = "normal";
		bias-disable; /* No Pull */
		power-source = <0>; /* VIN0 3.6V*/
		output-low; /* digital output, no invert */
		qcom,drive-strength = <3>; /* LOW strength */
		drive-push-pull; /* CMOS */
	};
	//dir-gpio
	dir_gpio: dir_gpio {
		pins = "gpio6";
		function = "normal";
		bias-disable; /* No Pull */
		power-source = <0>; /* VIN0 3.6V*/
		output-low; /* digital output, no invert */
		qcom,drive-strength = <3>; /* LOW strength */
		drive-push-pull; /* CMOS */
	};
};

&pmi8998_pwm_6 {
	qcom,ramp-index = <1>;
	//qcom,force-pwm-size = <9>;
	qcom,mode-select = <0>; /* PWM */
	qcom,period = <7>;
	#pwm-cells = <2>;
	status = "okay";
	qcom,pwm {
		qcom,duty = <3>;
		label = "pwm";
	};
};

&vendor  {
	motor_pl: motor_pl {
			compatible = "oppo-motor";
			interrupt-parent = <&tlmm>;
			interrupts = <120 0x2>;
			motor,irq-gpio = <&tlmm 120 0x2008>;
			pinctrl-names = "free_fall_input";
			pinctrl-0 = <&free_fall_input>;
	};
	motor_drv: motor_drv {
		compatible = "motor_drv-8834";
		pinctrl-names = "boost","pwm_config","vref_high_impedance","vref_gpio",
					"m0_high_impedance","m0_gpio","m1_gpio","sleep_gpio","dir_gpio","dir_switch_gpio_input_high","dir_switch_gpio_input_low";
		pinctrl-0 = <&boost>;
		pinctrl-1 = <&pwm_config>;
		pinctrl-2 = <&vref_high_impedance>;
		pinctrl-3 = <&vref_gpio>;
		pinctrl-4 = <&m0_high_impedance>;
		pinctrl-5 = <&m0_gpio>;
		pinctrl-6 = <&m1_gpio>;
		pinctrl-7 = <&sleep_gpio &sleep1_gpio>;
		pinctrl-8 = <&dir_gpio>;
		pinctrl-9 = <&dir_switch_gpio_input_high>;
		pinctrl-10 = <&dir_switch_gpio_input_low>;
		pwms = <&pmi8998_pwm_6 0 0>;
		qcom,boost-gpio = <&pm8998_gpios 7 0x00>;
		qcom,vref-gpio = <&pmi8998_gpios 10 0>;
		qcom,sleep-gpio = <&pmi8998_gpios 1 0>;
		qcom,sleep1-gpio = <&pmi8998_gpios 7 0>;
		qcom,dir-gpio = <&pmi8998_gpios 6 0>;
		qcom,m0-gpio = <&pmi8998_gpios 3 0>;
		qcom,m1-gpio = <&pmi8998_gpios 11 0>;
		qcom,step-gpio = <&pmi8998_gpios 8 0>;
		qcom,dir_switch-gpio = <&tlmm 129 0>;
	};
	motor_drv1: motor_drv1 {
		compatible = "motor_drv-220";
		pinctrl-names = "boost","pwm_config","sleep_gpio","dir_gpio","dir_switch_gpio_input_high","dir_switch_gpio_input_low","enable_gpio","pwm_config_as_gpio";
		pinctrl-0 = <&boost>;
		pinctrl-1 = <&pwm_config>;
		pinctrl-2 = <&sleep_gpio &sleep1_gpio>;
		pinctrl-3 = <&dir_gpio>;
		pinctrl-4 = <&dir_switch_gpio_input_high>;
		pinctrl-5 = <&dir_switch_gpio_input_low>;
		pinctrl-6 = <&enable_gpio>;
		pinctrl-7 = <&pwm_config_as_gpio>;
		pwms = <&pmi8998_pwm_6 0 0>;
		qcom,boost-gpio = <&pm8998_gpios 7 0x00>;
		qcom,sleep-gpio = <&pmi8998_gpios 1 0>;
		qcom,sleep1-gpio = <&pmi8998_gpios 7 0>;
		qcom,dir-gpio = <&pmi8998_gpios 6 0>;
		qcom,enable-gpio = <&pmi8998_gpios 3 0>;
		qcom,step-gpio = <&pmi8998_gpios 8 0>;
		qcom,dir_switch-gpio = <&tlmm 129 0>;
	};
	proximity_power: proximity_power {
		compatible = "proximity_power";
		pinctrl-names = "power_gpio_low","power_gpio_high";
		pinctrl-0 = <&power_gpio_low>;
		pinctrl-1 = <&power_gpio_high>;
		qcom,power_gpio = <&tlmm 63 0>;
	};
};
//#endif
